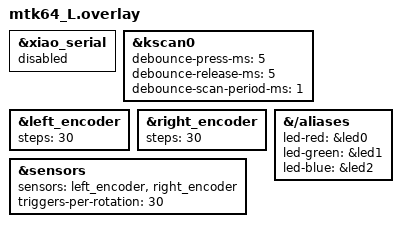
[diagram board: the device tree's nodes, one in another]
#include "mtk64.dtsi"

/*
&kscan0 {
    gpios
        = <&xiao_d 1 GPIO_ACTIVE_HIGH>
        , <&xiao_d 2 GPIO_ACTIVE_HIGH>
        , <&xiao_d 3 GPIO_ACTIVE_HIGH>
        , <&xiao_d 6 GPIO_ACTIVE_HIGH>
        , <&xiao_d 7 GPIO_ACTIVE_HIGH>
        , <&xiao_d 8 GPIO_ACTIVE_HIGH>
        , <&xiao_d 9 GPIO_ACTIVE_HIGH>
    ;
};
*/

/* ★ 左だけ抜けてたので追加：XIAOのUART(Serial)を無効化 */
&xiao_serial { status = "disabled"; };

/*
 * ★ チャタ対策
 * 以前は 15ms / 15ms / 2ms と強めにしていたが、原因は A/Z の読み取りが
 * 電池駆動時に不安定だったこと。mtk64_L.conf の
 * CONFIG_ZMK_KSCAN_CHARLIEPLEX_WAIT_BEFORE_INPUTS で読み取りが安定したので、
 * ZMK 標準の値に戻した（2026-10-15）。15ms だと押下が遅れ、速い連打では
 * 離しが成立せず押しっぱなし扱いになっていた。
 * 二重入力（チャタリング）が出たら 8ms / 8ms あたりに上げる。
 */
&kscan0 {
  debounce-press-ms = <5>;
  debounce-release-ms = <5>;
  debounce-scan-period-ms = <1>;
};

/* ここから下：ロータリーエンコーダー調整 */
&left_encoder {
    status = "okay";
    steps = <30>;
};

&right_encoder {
    status = "okay";
    steps = <30>;
};

&sensors {
    sensors = <&left_encoder &right_encoder>;
    triggers-per-rotation = <30>;
};

&{/aliases} {
  led-red = &led0;
  led-green = &led1;
  led-blue = &led2;
};
